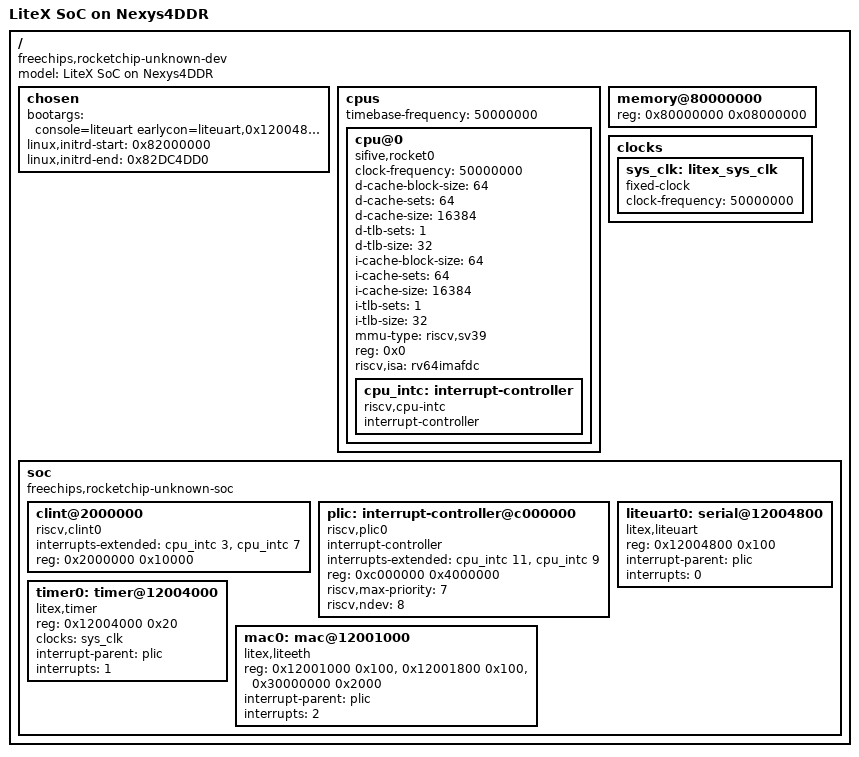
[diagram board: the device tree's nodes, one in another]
/dts-v1/;

/ {
    #address-cells = <1>;
    #size-cells = <1>;
    compatible = "freechips,rocketchip-unknown-dev";
    model = "LiteX SoC on Nexys4DDR";

    chosen {
        bootargs = "console=liteuart earlycon=liteuart,0x12004800 swiotlb=noforce rootwait root=/dev/ram0";
        linux,initrd-start = <0x82000000>;
        linux,initrd-end   = <0x82DC4DD0>; /* Ajuste conforme necessário */
    };

    cpus {
        #address-cells = <1>;
        #size-cells = <0>;
        timebase-frequency = <50000000>; // 50MHz

        cpu@0 {
            clock-frequency = <50000000>; // 50MHz
            compatible = "sifive,rocket0", "riscv";
            d-cache-block-size = <64>;
            d-cache-sets = <64>;
            d-cache-size = <16384>;
            d-tlb-sets = <1>;
            d-tlb-size = <32>;
            device_type = "cpu";
            i-cache-block-size = <64>;
            i-cache-sets = <64>;
            i-cache-size = <16384>;
            i-tlb-sets = <1>;
            i-tlb-size = <32>;
            mmu-type = "riscv,sv39";
            reg = <0x0>;
            riscv,isa = "rv64imafdc";
            status = "okay";

            cpu_intc: interrupt-controller {
                #interrupt-cells = <1>;
                compatible = "riscv,cpu-intc";
                interrupt-controller;
            };
        };
    };

    memory@80000000 {
        device_type = "memory";
        reg = <0x80000000 0x08000000>; /* 128MB conforme csr.csv */
    };

    clocks {
        sys_clk: litex_sys_clk {
            #clock-cells = <0>;
            compatible = "fixed-clock";
            clock-frequency = <50000000>;
        };
    };

    soc {
        #address-cells = <1>;
        #size-cells = <1>;
        compatible = "freechips,rocketchip-unknown-soc", "simple-bus";
        ranges;

        clint@2000000 {
            compatible = "riscv,clint0";
            interrupts-extended = <&cpu_intc 3 &cpu_intc 7>;
            reg = <0x2000000 0x10000>;
        };

        plic: interrupt-controller@c000000 {
            #interrupt-cells = <1>;
            compatible = "riscv,plic0";
            interrupt-controller;
            interrupts-extended = <&cpu_intc 11 &cpu_intc 9>;
            reg = <0xc000000 0x4000000>;
            riscv,max-priority = <7>;
            riscv,ndev = <8>;
        };

        liteuart0: serial@12004800 {
            compatible = "litex,liteuart";
            reg = <0x12004800 0x100>;
            interrupt-parent = <&plic>;
            interrupts = <0>; // uart_interrupt
        };

        timer0: timer@12004000 {
            compatible = "litex,timer";
            reg = <0x12004000 0x20>;
            clocks = <&sys_clk>;
            interrupt-parent = <&plic>;
            interrupts = <1>; // timer0_interrupt
        };

        mac0: mac@12001000 {
            compatible = "litex,liteeth";
            reg = <0x12001000 0x100>,
                  <0x12001800 0x100>,
                  <0x30000000 0x2000>;
            reg-names = "mac", "mdio", "buffer";
            interrupt-parent = <&plic>;
            interrupts = <2>; // ethmac_interrupt
        };
    };
};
